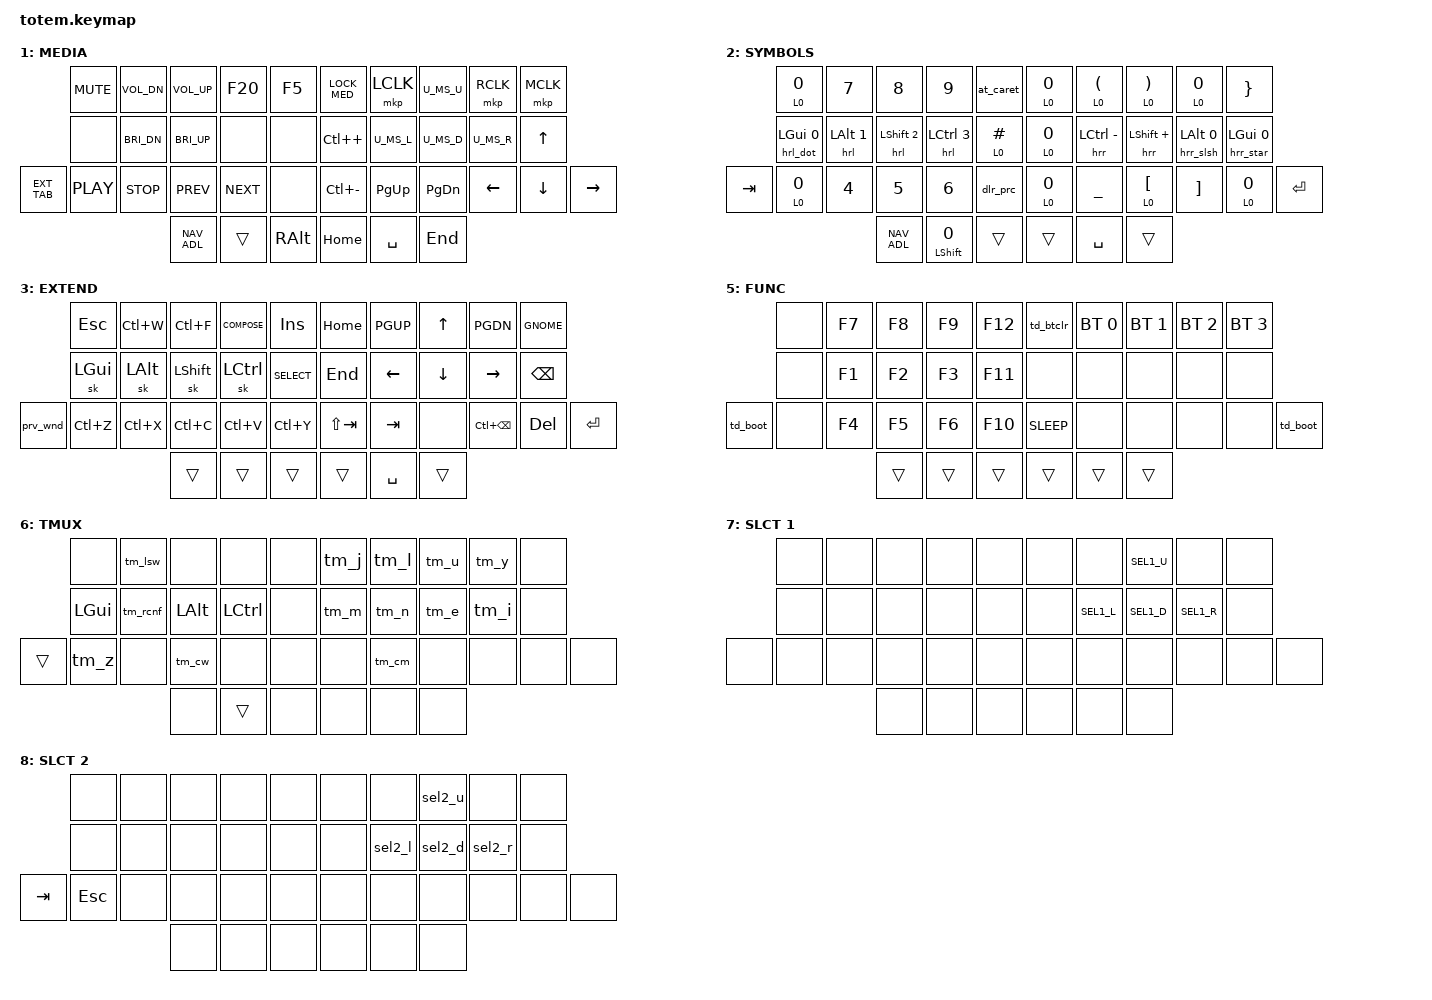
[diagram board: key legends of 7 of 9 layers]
//
//                                                        ▀▀▀▀▀     ▀▀▀▀▀          ▀▀█▀▀
//                                                        ▄▀▀▀▄  ▄  ▄▀▀▀▄  ▄  ▄▀▀▀▄  █  ▄▀▀▀▄
//                                                        █   █  █  █   █  █  █   █  █  █   █
//                                                         ▀▀▀   █   ▀▀▀   █   ▀▀▀   ▀   ▀▀▀
//                                                               █      ▄▄▄█▄▄▄    █   █  
//                                                               ▀      █  █  █     █▄█
//                                                             ▀▀▀▀▀    █  █  █      ▀
//                                                                      ▀  ▀  ▀
//
// ▄▄▄▄▄▄▄▄▄▄▄▄▄▄▄▄▄▄▄▄▄▄▄▄▄▄▄▄▄▄▄▄▄▄▄▄▄▄▄▄▄▄▄▄▄▄▄▄▄▄▄▄▄▄▄▄▄▄▄▄▄▄▄▄▄▄▄▄▄▄▄▄▄▄▄▄▄▄▄▄▄▄▄▄▄▄▄▄▄▄▄▄▄▄▄▄▄▄▄▄▄▄▄▄▄▄▄▄▄▄▄▄▄▄▄▄▄▄▄▄▄▄▄▄▄▄▄▄▄▄▄▄▄▄▄▄▄▄▄▄▄▄▄▄▄▄▄▄▄
       

#include <behaviors.dtsi>
#include <dt-bindings/zmk/bt.h>
#include <dt-bindings/zmk/keys.h>
#include <dt-bindings/zmk/mouse.h>
#include <dt-bindings/zmk/outputs.h>
#include <input/processors.dtsi>

#include "key-labels/totem.h"
#include "common.dtsi"
#include "macros.dtsi"
#include "macros_help.dtsi"
#include "macros_private.dtsi"
#include "macros_select.dtsi"
#include "macros_tmux.dtsi"
#include "combos.dtsi"
#include "adaptive_keys.dtsi"
#include "leader_keys.dtsi"
#include "behaviors.dtsi"

/ {
    // Totem-specific combos
    combos {
        compatible = "zmk,combos";
        combo_media {
            timeout-ms = <50>;
            slow-release;
            key-positions = <LB5 LM4>;
            bindings = <&tog MEDIA>;
            layers = <COLEMAK MEDIA>;
        };
        combo_undo {
            timeout-ms = <50>;
            key-positions = <LM4 LB3>;
            bindings = <&kp LC(Z)>;
            //layers = <COLEMAK>;
        };
    };
};

/ {
        keymap {
                compatible = "zmk,keymap";
// ▄▄▄▄▄▄▄▄▄▄▄▄▄▄▄▄▄▄▄▄▄▄▄▄▄▄▄▄▄▄▄▄▄▄▄▄▄▄▄▄▄▄▄▄▄▄▄▄▄▄▄▄▄▄▄▄▄▄▄▄▄▄▄▄▄▄▄▄▄▄▄▄▄▄▄▄▄▄▄▄▄▄▄▄▄▄▄▄▄▄▄▄▄▄▄▄▄▄▄▄▄▄▄▄▄▄▄▄▄▄▄▄▄▄▄▄▄▄▄▄▄▄▄▄▄▄▄▄▄▄▄▄▄▄▄▄▄▄▄▄▄▄▄▄▄▄▄▄▄

                default_layer {
//          ┏━━━━━━━━━━━━━━━━━━━━━━━━━━━━━━━━━━━━━━━┓
display-name= "COLEMK"                              ;
//          ┗━━━━━━━━━━━━━━━━━━━━━━━━━━━━━━━━━━━━━━━┛
//             ┏━━━━━━━━━━━┳━━━━━━━━━━━┳━━━━━━━━━━━┳━━━━━━━━━━━┳━━━━━━━━━━━┓   ┏━━━━━━━━━━━┳━━━━━━━━━━━┳━━━━━━━━━━━┳━━━━━━━━━━━┳━━━━━━━━━━━┓
//             ┃     Q     ┃     W     ┃     F     ┃     P     ┃     B     ┃   ┃     J     ┃     L     ┃     U     ┃     Y     ┃   BSPC    ┃
//             ┣━━━━━━━━━━━╋━━━━━━━━━━━╋━━━━━━━━━━━╋━━━━━━━━━━━╋━━━━━━━━━━━┫   ┣━━━━━━━━━━━╋━━━━━━━━━━━╋━━━━━━━━━━━╋━━━━━━━━━━━╋━━━━━━━━━━━┫
//             ┃     A     ┃     R     ┃     S     ┃     T     ┃     G     ┃   ┃     M     ┃     N     ┃     E     ┃     I     ┃     O     ┃
// ┏━━━━━━━━━━━╋━━━━━━━━━━━╋━━━━━━━━━━━╋━━━━━━━━━━━╋━━━━━━━━━━━╋━━━━━━━━━━━┫   ┣━━━━━━━━━━━╋━━━━━━━━━━━╋━━━━━━━━━━━╋━━━━━━━━━━━╋━━━━━━━━━━━╋━━━━━━━━━━━┓
// ┃    TAB    ┃     Z     ┃     X     ┃     C     ┃     D     ┃     V     ┃   ┃     K     ┃     H     ┃     ,     ┃     .     ┃     /     ┃    ENT    ┃
// ┗━━━━━━━━━━━┻━━━━━━━━━━━┻━━━━━━━━━━━╋━━━━━━━━━━━╋━━━━━━━━━━━╋━━━━━━━━━━━┫   ┣━━━━━━━━━━━╋━━━━━━━━━━━╋━━━━━━━━━━━╋━━━━━━━━━━━┻━━━━━━━━━━━┻━━━━━━━━━━━┛
//                                     ┃    DEL    ┃    TAB    ┃    SPC    ┃   ┃  SYMBOLS  ┃   SPACE   ┃   FUNC    ┃
//                                     ┗━━━━━━━━━━━┻━━━━━━━━━━━┻━━━━━━━━━━━┛   ┗━━━━━━━━━━━┻━━━━━━━━━━━┻━━━━━━━━━━━┛
 bindings = <
// ╷           ╷           ╷           ╷           ╷           ╷           ╷   ╷           ╷           ╷           ╷           ╷           ╷           ╷

                &kp Q       &kp W       &kp F       &kp P       &kp B           &kp J       &kp L       &kp U       &kp Y       &kp BSPC
                &hrl LGUI A &hrl LALT R &hrl LSHFT S &hrl LCTRL T &hrl RALT G   &hrr RALT M &hrr LCTRL N &hrr LSHFT E &hrr LALT I &hrr LGUI O
    MEDIA_TAB   &kp Z       &kp X       &kp C       &hrl RCTRL D  V_GREEK       K_GREEK     &hrr RCTRL H  &comm_grv   DOT_MACROS  SLASH_DIRS    MEDIA_ENT
                                        NAV_ADL     &kp LSHIFT  EXT_CAPS        SYMB_ALTGR  TMUX_SPC    FUNC_ADR
                        >;
                };
// ▄▄▄▄▄▄▄▄▄▄▄▄▄▄▄▄▄▄▄▄▄▄▄▄▄▄▄▄▄▄▄▄▄▄▄▄▄▄▄▄▄▄▄▄▄▄▄▄▄▄▄▄▄▄▄▄▄▄▄▄▄▄▄▄▄▄▄▄▄▄▄▄▄▄▄▄▄▄▄▄▄▄▄▄▄▄▄▄▄▄▄▄▄▄▄▄▄▄▄▄▄▄▄▄▄▄▄▄▄▄▄▄▄▄▄▄▄▄▄▄▄▄▄▄▄▄▄▄▄▄▄▄▄▄▄▄▄▄▄▄▄▄▄▄▄▄▄▄▄


                media_layer {
//          ┏━━━━━━━━━━━━━━━━━━━━━━━━━━━━━━━━━━━━━━━┓
display-name= "MEDIA"                               ;
//          ┗━━━━━━━━━━━━━━━━━━━━━━━━━━━━━━━━━━━━━━━┛
//             ┏━━━━━━━━━━━┳━━━━━━━━━━━┳━━━━━━━━━━━┳━━━━━━━━━━━┳━━━━━━━━━━━┓   ┏━━━━━━━━━━━┳━━━━━━━━━━━┳━━━━━━━━━━━┳━━━━━━━━━━━┳━━━━━━━━━━━┓
//             ┃           ┃           ┃           ┃           ┃           ┃   ┃           ┃           ┃           ┃           ┃           ┃
//             ┣━━━━━━━━━━━╋━━━━━━━━━━━╋━━━━━━━━━━━╋━━━━━━━━━━━╋━━━━━━━━━━━┫   ┣━━━━━━━━━━━╋━━━━━━━━━━━╋━━━━━━━━━━━╋━━━━━━━━━━━╋━━━━━━━━━━━┫
//             ┃           ┃           ┃           ┃           ┃           ┃   ┃           ┃           ┃           ┃           ┃           ┃
// ┏━━━━━━━━━━━╋━━━━━━━━━━━╋━━━━━━━━━━━╋━━━━━━━━━━━╋━━━━━━━━━━━╋━━━━━━━━━━━┫   ┣━━━━━━━━━━━╋━━━━━━━━━━━╋━━━━━━━━━━━╋━━━━━━━━━━━╋━━━━━━━━━━━╋━━━━━━━━━━━┓
// ┃           ┃           ┃           ┃           ┃           ┃           ┃   ┃           ┃           ┃           ┃           ┃           ┃           ┃
// ┗━━━━━━━━━━━┻━━━━━━━━━━━┻━━━━━━━━━━━╋━━━━━━━━━━━╋━━━━━━━━━━━╋━━━━━━━━━━━┫   ┣━━━━━━━━━━━╋━━━━━━━━━━━╋━━━━━━━━━━━╋━━━━━━━━━━━┻━━━━━━━━━━━┻━━━━━━━━━━━┛
//                                     ┃           ┃           ┃           ┃   ┃           ┃           ┃           ┃
//                                     ┗━━━━━━━━━━━┻━━━━━━━━━━━┻━━━━━━━━━━━┛   ┗━━━━━━━━━━━┻━━━━━━━━━━━┻━━━━━━━━━━━┛
 bindings = <
// ╷           ╷           ╷           ╷           ╷           ╷           ╷   ╷           ╷           ╷           ╷           ╷           ╷           ╷

                &kp C_MUTE  &kp C_VOL_DN &kp C_VOL_UP &kp F20   &kp F5          LOCK_MED    &mkp LCLK   U_MS_U      &mkp RCLK    &mkp MCLK
                &none       &kp C_BRI_DN &kp C_BRI_UP &none     &none           &kp LC(PLUS) U_MS_L     U_MS_D      U_MS_R       &kp UP
    EXT_TAB     &kp C_PLAY  &kp C_STOP   &kp C_PREV   &kp C_NEXT &none          &kp LC(MINUS) &kp PG_UP &kp PG_DN   &kp LEFT     &kp DOWN    &kp RIGHT
                                            NAV_ADL   &trans    &kp RALT        &kp HOME    &kp SPC     &kp END
                        >;
                };

// ▄▄▄▄▄▄▄▄▄▄▄▄▄▄▄▄▄▄▄▄▄▄▄▄▄▄▄▄▄▄▄▄▄▄▄▄▄▄▄▄▄▄▄▄▄▄▄▄▄▄▄▄▄▄▄▄▄▄▄▄▄▄▄▄▄▄▄▄▄▄▄▄▄▄▄▄▄▄▄▄▄▄▄▄▄▄▄▄▄▄▄▄▄▄▄▄▄▄▄▄▄▄▄▄▄▄▄▄▄▄▄▄▄▄▄▄▄▄▄▄▄▄▄▄▄▄▄▄▄▄▄▄▄▄▄▄▄▄▄▄▄▄▄▄▄▄▄▄▄


                symbols_layer {
//          ┏━━━━━━━━━━━━━━━━━━━━━━━━━━━━━━━━━━━━━━━┓
display-name= "SYMBOLS"                             ;
//          ┗━━━━━━━━━━━━━━━━━━━━━━━━━━━━━━━━━━━━━━━┛
//             ┏━━━━━━━━━━━┳━━━━━━━━━━━┳━━━━━━━━━━━┳━━━━━━━━━━━┳━━━━━━━━━━━┓   ┏━━━━━━━━━━━┳━━━━━━━━━━━┳━━━━━━━━━━━┳━━━━━━━━━━━┳━━━━━━━━━━━┓
//             ┃           ┃           ┃           ┃           ┃           ┃   ┃           ┃           ┃           ┃           ┃           ┃
//             ┣━━━━━━━━━━━╋━━━━━━━━━━━╋━━━━━━━━━━━╋━━━━━━━━━━━╋━━━━━━━━━━━┫   ┣━━━━━━━━━━━╋━━━━━━━━━━━╋━━━━━━━━━━━╋━━━━━━━━━━━╋━━━━━━━━━━━┫
//             ┃           ┃           ┃           ┃           ┃           ┃   ┃           ┃           ┃           ┃           ┃           ┃
// ┏━━━━━━━━━━━╋━━━━━━━━━━━╋━━━━━━━━━━━╋━━━━━━━━━━━╋━━━━━━━━━━━╋━━━━━━━━━━━┫   ┣━━━━━━━━━━━╋━━━━━━━━━━━╋━━━━━━━━━━━╋━━━━━━━━━━━╋━━━━━━━━━━━╋━━━━━━━━━━━┓
// ┃           ┃           ┃           ┃           ┃           ┃           ┃   ┃           ┃           ┃           ┃           ┃           ┃           ┃
// ┗━━━━━━━━━━━┻━━━━━━━━━━━┻━━━━━━━━━━━╋━━━━━━━━━━━╋━━━━━━━━━━━╋━━━━━━━━━━━┫   ┣━━━━━━━━━━━╋━━━━━━━━━━━╋━━━━━━━━━━━╋━━━━━━━━━━━┻━━━━━━━━━━━┻━━━━━━━━━━━┛
//                                     ┃           ┃           ┃           ┃   ┃           ┃           ┃           ┃
//                                     ┗━━━━━━━━━━━┻━━━━━━━━━━━┻━━━━━━━━━━━┛   ┗━━━━━━━━━━━┻━━━━━━━━━━━┻━━━━━━━━━━━┛
 bindings = <
// ╷           ╷           ╷           ╷           ╷           ╷           ╷   ╷           ╷           ╷           ╷           ╷           ╷           ╷

                &ht_gt 0 0  &kp N7      &kp N8      &kp N9      &at_caret       &ht_amps 0 0 &ht_lpar 0 LPAR &ht_rpar 0 RPAR  &ht_lbrc 0 0 &kp RBRC
                &hrl_dot LGUI 0 &hrl LALT N1 &hrl LSHFT N2 &hrl LCTRL N3 &ht_hash 0 HASH       &ht_equl 0 0 &hrr LCTRL MINUS &hrr LSHFT PLUS &hrr_slsh LALT 0 &hrr_star LGUI 0
    &kp TAB     &ht_lt 0 0  &kp N4      &kp N5      &kp N6      &dlr_prc        &ht_excl 0 0 &kp UNDER  &ht_lbkt 0 LBKT &kp RBKT &ht_pipe 0 0  &kp ENTER
                                            NAV_ADL &mt LSHIFT N0 &trans        &trans  &kp SPC  &trans
                        >;
                };

// ▄▄▄▄▄▄▄▄▄▄▄▄▄▄▄▄▄▄▄▄▄▄▄▄▄▄▄▄▄▄▄▄▄▄▄▄▄▄▄▄▄▄▄▄▄▄▄▄▄▄▄▄▄▄▄▄▄▄▄▄▄▄▄▄▄▄▄▄▄▄▄▄▄▄▄▄▄▄▄▄▄▄▄▄▄▄▄▄▄▄▄▄▄▄▄▄▄▄▄▄▄▄▄▄▄▄▄▄▄▄▄▄▄▄▄▄▄▄▄▄▄▄▄▄▄▄▄▄▄▄▄▄▄▄▄▄▄▄▄▄▄▄▄▄▄▄▄▄▄


                extend_layer {
//          ┏━━━━━━━━━━━━━━━━━━━━━━━━━━━━━━━━━━━━━━━┓
display-name= "EXTEND"                              ;
//          ┗━━━━━━━━━━━━━━━━━━━━━━━━━━━━━━━━━━━━━━━┛
//             ┏━━━━━━━━━━━┳━━━━━━━━━━━┳━━━━━━━━━━━┳━━━━━━━━━━━┳━━━━━━━━━━━┓   ┏━━━━━━━━━━━┳━━━━━━━━━━━┳━━━━━━━━━━━┳━━━━━━━━━━━┳━━━━━━━━━━━┓
//             ┃           ┃           ┃           ┃           ┃           ┃   ┃           ┃           ┃           ┃           ┃           ┃
//             ┣━━━━━━━━━━━╋━━━━━━━━━━━╋━━━━━━━━━━━╋━━━━━━━━━━━╋━━━━━━━━━━━┫   ┣━━━━━━━━━━━╋━━━━━━━━━━━╋━━━━━━━━━━━╋━━━━━━━━━━━╋━━━━━━━━━━━┫
//             ┃           ┃           ┃           ┃           ┃           ┃   ┃           ┃           ┃           ┃           ┃           ┃
// ┏━━━━━━━━━━━╋━━━━━━━━━━━╋━━━━━━━━━━━╋━━━━━━━━━━━╋━━━━━━━━━━━╋━━━━━━━━━━━┫   ┣━━━━━━━━━━━╋━━━━━━━━━━━╋━━━━━━━━━━━╋━━━━━━━━━━━╋━━━━━━━━━━━╋━━━━━━━━━━━┓
// ┃           ┃           ┃           ┃           ┃           ┃           ┃   ┃           ┃           ┃           ┃           ┃           ┃           ┃
// ┗━━━━━━━━━━━┻━━━━━━━━━━━┻━━━━━━━━━━━╋━━━━━━━━━━━╋━━━━━━━━━━━╋━━━━━━━━━━━┫   ┣━━━━━━━━━━━╋━━━━━━━━━━━╋━━━━━━━━━━━╋━━━━━━━━━━━┻━━━━━━━━━━━┻━━━━━━━━━━━┛
//                                     ┃           ┃           ┃           ┃   ┃           ┃           ┃           ┃
//                                     ┗━━━━━━━━━━━┻━━━━━━━━━━━┻━━━━━━━━━━━┛   ┗━━━━━━━━━━━┻━━━━━━━━━━━┻━━━━━━━━━━━┛
 bindings = <
// ╷           ╷           ╷           ╷           ╷           ╷           ╷   ╷           ╷           ╷           ╷           ╷           ╷           ╷

                &kp ESC     &kp LC(W)   &kp LC(F)   COMPOSE     &kp INS         &kp HOME    &kp PGUP    &kp UP      &kp PGDN    GNOME
                &sk LGUI    &sk LALT    &sk LSHFT   &sk LCTRL   SELECT          &kp END     &kp LEFT    &kp DOWN    &kp RIGHT   &kp BSPC
    &prv_wnd    &kp LC(Z)   &kp LC(X)   &kp LC(C)   &kp LC(V)   &kp LC(Y)       &kp LS(TAB) &kp TAB     &none       &kp LC(BSPC) &kp DEL    &kp ENTER
                                        &trans      &trans      &trans          &trans      &kp SPC     &trans
                        >;
                };

// ▄▄▄▄▄▄▄▄▄▄▄▄▄▄▄▄▄▄▄▄▄▄▄▄▄▄▄▄▄▄▄▄▄▄▄▄▄▄▄▄▄▄▄▄▄▄▄▄▄▄▄▄▄▄▄▄▄▄▄▄▄▄▄▄▄▄▄▄▄▄▄▄▄▄▄▄▄▄▄▄▄▄▄▄▄▄▄▄▄▄▄▄▄▄▄▄▄▄▄▄▄▄▄▄▄▄▄▄▄▄▄▄▄▄▄▄▄▄▄▄▄▄▄▄▄▄▄▄▄▄▄▄▄▄▄▄▄▄▄▄▄▄▄▄▄▄▄▄▄


                nav_layer {
//          ┏━━━━━━━━━━━━━━━━━━━━━━━━━━━━━━━━━━━━━━━┓
display-name= "NAV"                                 ;
//          ┗━━━━━━━━━━━━━━━━━━━━━━━━━━━━━━━━━━━━━━━┛
//             ┏━━━━━━━━━━━┳━━━━━━━━━━━┳━━━━━━━━━━━┳━━━━━━━━━━━┳━━━━━━━━━━━┓   ┏━━━━━━━━━━━┳━━━━━━━━━━━┳━━━━━━━━━━━┳━━━━━━━━━━━┳━━━━━━━━━━━┓
//             ┃           ┃           ┃           ┃           ┃           ┃   ┃           ┃           ┃           ┃           ┃           ┃
//             ┣━━━━━━━━━━━╋━━━━━━━━━━━╋━━━━━━━━━━━╋━━━━━━━━━━━╋━━━━━━━━━━━┫   ┣━━━━━━━━━━━╋━━━━━━━━━━━╋━━━━━━━━━━━╋━━━━━━━━━━━╋━━━━━━━━━━━┫
//             ┃           ┃           ┃           ┃           ┃           ┃   ┃           ┃           ┃           ┃           ┃           ┃
// ┏━━━━━━━━━━━╋━━━━━━━━━━━╋━━━━━━━━━━━╋━━━━━━━━━━━╋━━━━━━━━━━━╋━━━━━━━━━━━┫   ┣━━━━━━━━━━━╋━━━━━━━━━━━╋━━━━━━━━━━━╋━━━━━━━━━━━╋━━━━━━━━━━━╋━━━━━━━━━━━┓
// ┃           ┃           ┃           ┃           ┃           ┃           ┃   ┃           ┃           ┃           ┃           ┃           ┃           ┃
// ┗━━━━━━━━━━━┻━━━━━━━━━━━┻━━━━━━━━━━━╋━━━━━━━━━━━╋━━━━━━━━━━━╋━━━━━━━━━━━┫   ┣━━━━━━━━━━━╋━━━━━━━━━━━╋━━━━━━━━━━━╋━━━━━━━━━━━┻━━━━━━━━━━━┻━━━━━━━━━━━┛
//                                     ┃           ┃           ┃           ┃   ┃           ┃           ┃           ┃
//                                     ┗━━━━━━━━━━━┻━━━━━━━━━━━┻━━━━━━━━━━━┛   ┗━━━━━━━━━━━┻━━━━━━━━━━━┻━━━━━━━━━━━┛
 bindings = <
// ╷           ╷           ╷           ╷           ╷           ╷           ╷   ╷           ╷           ╷           ╷           ╷           ╷           ╷

                APP_TRSM    APP_FFOX    APP_FILE    APP_CODE    APP_JOPL        &none       &kp LA(N1)  &kp LA(N2)  &kp LA(N3)  &kp LA(N4)
                &altesc     APP_SIGN    APP_SLAC    APP_BTRM    APP_STRM        &kp LC(PGUP) &kp LG(F1) &kp LG(F2)  &kp LG(F3)  &kp LG(F4)
    &alttab     &altgrv     APP_SCRP  &kp LC(LS(C)) &kp LC(LS(V)) APP_NTRM      &kp LC(PGDN) TAB_L      TAB_R       &srch_nxt   &srch_prv   &kp K_APP
                                        &trans      &trans      &trans          &kp LA(LEFT) &kp SPC    &kp LA(RIGHT)
                        >;
                };

// ▄▄▄▄▄▄▄▄▄▄▄▄▄▄▄▄▄▄▄▄▄▄▄▄▄▄▄▄▄▄▄▄▄▄▄▄▄▄▄▄▄▄▄▄▄▄▄▄▄▄▄▄▄▄▄▄▄▄▄▄▄▄▄▄▄▄▄▄▄▄▄▄▄▄▄▄▄▄▄▄▄▄▄▄▄▄▄▄▄▄▄▄▄▄▄▄▄▄▄▄▄▄▄▄▄▄▄▄▄▄▄▄▄▄▄▄▄▄▄▄▄▄▄▄▄▄▄▄▄▄▄▄▄▄▄▄▄▄▄▄▄▄▄▄▄▄▄▄▄


                func_layer {
//          ┏━━━━━━━━━━━━━━━━━━━━━━━━━━━━━━━━━━━━━━━┓
display-name= "FUNC"                                ;
//          ┗━━━━━━━━━━━━━━━━━━━━━━━━━━━━━━━━━━━━━━━┛
//             ┏━━━━━━━━━━━┳━━━━━━━━━━━┳━━━━━━━━━━━┳━━━━━━━━━━━┳━━━━━━━━━━━┓   ┏━━━━━━━━━━━┳━━━━━━━━━━━┳━━━━━━━━━━━┳━━━━━━━━━━━┳━━━━━━━━━━━┓
//             ┃           ┃           ┃           ┃           ┃           ┃   ┃           ┃           ┃           ┃           ┃           ┃
//             ┣━━━━━━━━━━━╋━━━━━━━━━━━╋━━━━━━━━━━━╋━━━━━━━━━━━╋━━━━━━━━━━━┫   ┣━━━━━━━━━━━╋━━━━━━━━━━━╋━━━━━━━━━━━╋━━━━━━━━━━━╋━━━━━━━━━━━┫
//             ┃           ┃           ┃           ┃           ┃           ┃   ┃           ┃           ┃           ┃           ┃           ┃
// ┏━━━━━━━━━━━╋━━━━━━━━━━━╋━━━━━━━━━━━╋━━━━━━━━━━━╋━━━━━━━━━━━╋━━━━━━━━━━━┫   ┣━━━━━━━━━━━╋━━━━━━━━━━━╋━━━━━━━━━━━╋━━━━━━━━━━━╋━━━━━━━━━━━╋━━━━━━━━━━━┓
// ┃           ┃           ┃           ┃           ┃           ┃           ┃   ┃           ┃           ┃           ┃           ┃           ┃           ┃
// ┗━━━━━━━━━━━┻━━━━━━━━━━━┻━━━━━━━━━━━╋━━━━━━━━━━━╋━━━━━━━━━━━╋━━━━━━━━━━━┫   ┣━━━━━━━━━━━╋━━━━━━━━━━━╋━━━━━━━━━━━╋━━━━━━━━━━━┻━━━━━━━━━━━┻━━━━━━━━━━━┛
//                                     ┃           ┃           ┃           ┃   ┃           ┃           ┃           ┃
//                                     ┗━━━━━━━━━━━┻━━━━━━━━━━━┻━━━━━━━━━━━┛   ┗━━━━━━━━━━━┻━━━━━━━━━━━┻━━━━━━━━━━━┛
 bindings = <
// ╷           ╷           ╷           ╷           ╷           ╷           ╷   ╷           ╷           ╷           ╷           ╷           ╷           ╷

                &none       &kp F7      &kp F8      &kp F9      &kp F12         &td_btclr   &bt BT_SEL 0 &bt BT_SEL 1 &bt BT_SEL 2 &bt BT_SEL 3
                &none       &kp F1      &kp F2      &kp F3      &kp F11         &none       &none       &none       &none       &none
    &td_boot    &none       &kp F4      &kp F5      &kp F6      &kp F10         &kp C_SLEEP &none       &none       &none       &none        &td_boot
                                        &trans      &trans      &trans          &trans      &trans      &trans
                        >;
                };

// ▄▄▄▄▄▄▄▄▄▄▄▄▄▄▄▄▄▄▄▄▄▄▄▄▄▄▄▄▄▄▄▄▄▄▄▄▄▄▄▄▄▄▄▄▄▄▄▄▄▄▄▄▄▄▄▄▄▄▄▄▄▄▄▄▄▄▄▄▄▄▄▄▄▄▄▄▄▄▄▄▄▄▄▄▄▄▄▄▄▄▄▄▄▄▄▄▄▄▄▄▄▄▄▄▄▄▄▄▄▄▄▄▄▄▄▄▄▄▄▄▄▄▄▄▄▄▄▄▄▄▄▄▄▄▄▄▄▄▄▄▄▄▄▄▄▄▄▄▄


                tmux_layer {
//          ┏━━━━━━━━━━━━━━━━━━━━━━━━━━━━━━━━━━━━━━━┓
display-name= "TMUX"                                ;
//          ┗━━━━━━━━━━━━━━━━━━━━━━━━━━━━━━━━━━━━━━━┛
//             ┏━━━━━━━━━━━┳━━━━━━━━━━━┳━━━━━━━━━━━┳━━━━━━━━━━━┳━━━━━━━━━━━┓   ┏━━━━━━━━━━━┳━━━━━━━━━━━┳━━━━━━━━━━━┳━━━━━━━━━━━┳━━━━━━━━━━━┓
//             ┃           ┃           ┃           ┃           ┃           ┃   ┃           ┃           ┃           ┃           ┃           ┃
//             ┣━━━━━━━━━━━╋━━━━━━━━━━━╋━━━━━━━━━━━╋━━━━━━━━━━━╋━━━━━━━━━━━┫   ┣━━━━━━━━━━━╋━━━━━━━━━━━╋━━━━━━━━━━━╋━━━━━━━━━━━╋━━━━━━━━━━━┫
//             ┃           ┃           ┃           ┃           ┃           ┃   ┃           ┃           ┃           ┃           ┃           ┃
// ┏━━━━━━━━━━━╋━━━━━━━━━━━╋━━━━━━━━━━━╋━━━━━━━━━━━╋━━━━━━━━━━━╋━━━━━━━━━━━┫   ┣━━━━━━━━━━━╋━━━━━━━━━━━╋━━━━━━━━━━━╋━━━━━━━━━━━╋━━━━━━━━━━━╋━━━━━━━━━━━┓
// ┃           ┃           ┃           ┃           ┃           ┃           ┃   ┃           ┃           ┃           ┃           ┃           ┃           ┃
// ┗━━━━━━━━━━━┻━━━━━━━━━━━┻━━━━━━━━━━━╋━━━━━━━━━━━╋━━━━━━━━━━━╋━━━━━━━━━━━┫   ┣━━━━━━━━━━━╋━━━━━━━━━━━╋━━━━━━━━━━━╋━━━━━━━━━━━┻━━━━━━━━━━━┻━━━━━━━━━━━┛
//                                     ┃           ┃           ┃           ┃   ┃           ┃           ┃           ┃
//                                     ┗━━━━━━━━━━━┻━━━━━━━━━━━┻━━━━━━━━━━━┛   ┗━━━━━━━━━━━┻━━━━━━━━━━━┻━━━━━━━━━━━┛
 bindings = <
// ╷           ╷           ╷           ╷           ╷           ╷           ╷   ╷           ╷           ╷           ╷           ╷           ╷           ╷

                &none       &tm_lsw      &none      &none       &none           &tm_j       &tm_l       &tm_u       &tm_y       &none
                &kp LGUI    &tm_rcnf     &kp LALT   &kp LCTL    &none           &tm_m       &tm_n       &tm_e       &tm_i       &none
    &trans      &tm_z       &none        &tm_cw     &none       &none           &none       &tm_cm      &none       &none       &none       &none
                                         &none      &trans      &none           &none       &none       &none
                        >;
                };

// ▄▄▄▄▄▄▄▄▄▄▄▄▄▄▄▄▄▄▄▄▄▄▄▄▄▄▄▄▄▄▄▄▄▄▄▄▄▄▄▄▄▄▄▄▄▄▄▄▄▄▄▄▄▄▄▄▄▄▄▄▄▄▄▄▄▄▄▄▄▄▄▄▄▄▄▄▄▄▄▄▄▄▄▄▄▄▄▄▄▄▄▄▄▄▄▄▄▄▄▄▄▄▄▄▄▄▄▄▄▄▄▄▄▄▄▄▄▄▄▄▄▄▄▄▄▄▄▄▄▄▄▄▄▄▄▄▄▄▄▄▄▄▄▄▄▄▄▄▄


                select1_layer {
//          ┏━━━━━━━━━━━━━━━━━━━━━━━━━━━━━━━━━━━━━━━┓
display-name= "SLCT 1"                              ;
//          ┗━━━━━━━━━━━━━━━━━━━━━━━━━━━━━━━━━━━━━━━┛
//             ┏━━━━━━━━━━━┳━━━━━━━━━━━┳━━━━━━━━━━━┳━━━━━━━━━━━┳━━━━━━━━━━━┓   ┏━━━━━━━━━━━┳━━━━━━━━━━━┳━━━━━━━━━━━┳━━━━━━━━━━━┳━━━━━━━━━━━┓
//             ┃           ┃           ┃           ┃           ┃           ┃   ┃           ┃           ┃           ┃           ┃           ┃
//             ┣━━━━━━━━━━━╋━━━━━━━━━━━╋━━━━━━━━━━━╋━━━━━━━━━━━╋━━━━━━━━━━━┫   ┣━━━━━━━━━━━╋━━━━━━━━━━━╋━━━━━━━━━━━╋━━━━━━━━━━━╋━━━━━━━━━━━┫
//             ┃           ┃           ┃           ┃           ┃           ┃   ┃           ┃           ┃           ┃           ┃           ┃
// ┏━━━━━━━━━━━╋━━━━━━━━━━━╋━━━━━━━━━━━╋━━━━━━━━━━━╋━━━━━━━━━━━╋━━━━━━━━━━━┫   ┣━━━━━━━━━━━╋━━━━━━━━━━━╋━━━━━━━━━━━╋━━━━━━━━━━━╋━━━━━━━━━━━╋━━━━━━━━━━━┓
// ┃           ┃           ┃           ┃           ┃           ┃           ┃   ┃           ┃           ┃           ┃           ┃           ┃           ┃
// ┗━━━━━━━━━━━┻━━━━━━━━━━━┻━━━━━━━━━━━╋━━━━━━━━━━━╋━━━━━━━━━━━╋━━━━━━━━━━━┫   ┣━━━━━━━━━━━╋━━━━━━━━━━━╋━━━━━━━━━━━╋━━━━━━━━━━━┻━━━━━━━━━━━┻━━━━━━━━━━━┛
//                                     ┃           ┃           ┃           ┃   ┃           ┃           ┃           ┃
//                                     ┗━━━━━━━━━━━┻━━━━━━━━━━━┻━━━━━━━━━━━┛   ┗━━━━━━━━━━━┻━━━━━━━━━━━┻━━━━━━━━━━━┛
 bindings = <
// ╷           ╷           ╷           ╷           ╷           ╷           ╷   ╷           ╷           ╷           ╷           ╷           ╷           ╷

                &none      &none        &none       &none       &none           &none       &none       SEL1_U      &none       &none
                &none      &none        &none       &none       &none           &none       SEL1_L      SEL1_D      SEL1_R      &none
    &none       &none      &none        &none       &none       &none           &none       &none       &none       &none       &none       &none
                                        &none       &none       &none           &none       &none       &none
                        >;
                };

// ▄▄▄▄▄▄▄▄▄▄▄▄▄▄▄▄▄▄▄▄▄▄▄▄▄▄▄▄▄▄▄▄▄▄▄▄▄▄▄▄▄▄▄▄▄▄▄▄▄▄▄▄▄▄▄▄▄▄▄▄▄▄▄▄▄▄▄▄▄▄▄▄▄▄▄▄▄▄▄▄▄▄▄▄▄▄▄▄▄▄▄▄▄▄▄▄▄▄▄▄▄▄▄▄▄▄▄▄▄▄▄▄▄▄▄▄▄▄▄▄▄▄▄▄▄▄▄▄▄▄▄▄▄▄▄▄▄▄▄▄▄▄▄▄▄▄▄▄▄


                select2_layer {
//          ┏━━━━━━━━━━━━━━━━━━━━━━━━━━━━━━━━━━━━━━━┓
display-name= "SLCT 2"                              ;
//          ┗━━━━━━━━━━━━━━━━━━━━━━━━━━━━━━━━━━━━━━━┛
//             ┏━━━━━━━━━━━┳━━━━━━━━━━━┳━━━━━━━━━━━┳━━━━━━━━━━━┳━━━━━━━━━━━┓   ┏━━━━━━━━━━━┳━━━━━━━━━━━┳━━━━━━━━━━━┳━━━━━━━━━━━┳━━━━━━━━━━━┓
//             ┃           ┃           ┃           ┃           ┃           ┃   ┃           ┃           ┃           ┃           ┃           ┃
//             ┣━━━━━━━━━━━╋━━━━━━━━━━━╋━━━━━━━━━━━╋━━━━━━━━━━━╋━━━━━━━━━━━┫   ┣━━━━━━━━━━━╋━━━━━━━━━━━╋━━━━━━━━━━━╋━━━━━━━━━━━╋━━━━━━━━━━━┫
//             ┃           ┃           ┃           ┃           ┃           ┃   ┃           ┃           ┃           ┃           ┃           ┃
// ┏━━━━━━━━━━━╋━━━━━━━━━━━╋━━━━━━━━━━━╋━━━━━━━━━━━╋━━━━━━━━━━━╋━━━━━━━━━━━┫   ┣━━━━━━━━━━━╋━━━━━━━━━━━╋━━━━━━━━━━━╋━━━━━━━━━━━╋━━━━━━━━━━━╋━━━━━━━━━━━┓
// ┃           ┃           ┃           ┃           ┃           ┃           ┃   ┃           ┃           ┃           ┃           ┃           ┃           ┃
// ┗━━━━━━━━━━━┻━━━━━━━━━━━┻━━━━━━━━━━━╋━━━━━━━━━━━╋━━━━━━━━━━━╋━━━━━━━━━━━┫   ┣━━━━━━━━━━━╋━━━━━━━━━━━╋━━━━━━━━━━━╋━━━━━━━━━━━┻━━━━━━━━━━━┻━━━━━━━━━━━┛
//                                     ┃           ┃           ┃           ┃   ┃           ┃           ┃           ┃
//                                     ┗━━━━━━━━━━━┻━━━━━━━━━━━┻━━━━━━━━━━━┛   ┗━━━━━━━━━━━┻━━━━━━━━━━━┻━━━━━━━━━━━┛
 bindings = <
// ╷           ╷           ╷           ╷           ╷           ╷           ╷   ╷           ╷           ╷           ╷           ╷           ╷           ╷

                &none      &none        &none       &none       &none           &none       &none       &sel2_u     &none       &none
                &none      &none        &none       &none       &none           &none       &sel2_l     &sel2_d     &sel2_r     &none
    &kp TAB     &kp ESC    &none        &none       &none       &none           &none       &none       &none       &none       &none       &none
                                        &none       &none       &none           &none       &none       &none
                        >;
                };
// ▄▄▄▄▄▄▄▄▄▄▄▄▄▄▄▄▄▄▄▄▄▄▄▄▄▄▄▄▄▄▄▄▄▄▄▄▄▄▄▄▄▄▄▄▄▄▄▄▄▄▄▄▄▄▄▄▄▄▄▄▄▄▄▄▄▄▄▄▄▄▄▄▄▄▄▄▄▄▄▄▄▄▄▄▄▄▄▄▄▄▄▄▄▄▄▄▄▄▄▄▄▄▄▄▄▄▄▄▄▄▄▄▄▄▄▄▄▄▄▄▄▄▄▄▄▄▄▄▄▄▄▄▄▄▄▄▄▄▄▄▄▄▄▄▄▄▄▄▄

#if 0
                none_layer {
//          ┏━━━━━━━━━━━━━━━━━━━━━━━━━━━━━━━━━━━━━━━┓
display-name= "NONE"                                ;
//          ┗━━━━━━━━━━━━━━━━━━━━━━━━━━━━━━━━━━━━━━━┛
//             ┏━━━━━━━━━━━┳━━━━━━━━━━━┳━━━━━━━━━━━┳━━━━━━━━━━━┳━━━━━━━━━━━┓   ┏━━━━━━━━━━━┳━━━━━━━━━━━┳━━━━━━━━━━━┳━━━━━━━━━━━┳━━━━━━━━━━━┓
//             ┃           ┃           ┃           ┃           ┃           ┃   ┃           ┃           ┃           ┃           ┃           ┃
//             ┣━━━━━━━━━━━╋━━━━━━━━━━━╋━━━━━━━━━━━╋━━━━━━━━━━━╋━━━━━━━━━━━┫   ┣━━━━━━━━━━━╋━━━━━━━━━━━╋━━━━━━━━━━━╋━━━━━━━━━━━╋━━━━━━━━━━━┫
//             ┃           ┃           ┃           ┃           ┃           ┃   ┃           ┃           ┃           ┃           ┃           ┃
// ┏━━━━━━━━━━━╋━━━━━━━━━━━╋━━━━━━━━━━━╋━━━━━━━━━━━╋━━━━━━━━━━━╋━━━━━━━━━━━┫   ┣━━━━━━━━━━━╋━━━━━━━━━━━╋━━━━━━━━━━━╋━━━━━━━━━━━╋━━━━━━━━━━━╋━━━━━━━━━━━┓
// ┃           ┃           ┃           ┃           ┃           ┃           ┃   ┃           ┃           ┃           ┃           ┃           ┃           ┃
// ┗━━━━━━━━━━━┻━━━━━━━━━━━┻━━━━━━━━━━━╋━━━━━━━━━━━╋━━━━━━━━━━━╋━━━━━━━━━━━┫   ┣━━━━━━━━━━━╋━━━━━━━━━━━╋━━━━━━━━━━━╋━━━━━━━━━━━┻━━━━━━━━━━━┻━━━━━━━━━━━┛
//                                     ┃           ┃           ┃           ┃   ┃           ┃           ┃           ┃
//                                     ┗━━━━━━━━━━━┻━━━━━━━━━━━┻━━━━━━━━━━━┛   ┗━━━━━━━━━━━┻━━━━━━━━━━━┻━━━━━━━━━━━┛
 bindings = <
// ╷           ╷           ╷           ╷           ╷           ╷           ╷   ╷           ╷           ╷           ╷           ╷           ╷           ╷

                &none      &none        &none       &none       &none           &none       &none       &none       &none       &none
                &none      &none        &none       &none       &none           &none       &none       &none       &none       &none
    &none       &none      &none        &none       &none       &none           &none       &none       &none       &none       &none       &none
                                        &none       &none       &none           &none       &none       &none
                        >;
                };
#endif
        };
};
